VERSION ""

NS_ :

BS_:

BU_: TestBoard DummyBoard

BO_ 2147483655 InitTestphase: 2 TestBoard
 SG_ TestNumber : 8|8@1+ (1,0) [0|0] "" TestBoard
 SG_ TestVersion : 0|8@1+ (1,0) [0|0] "" TestBoard

BO_ 2147483666 TestMessage1: 1 TestBoard
 SG_ TestSignal : 0|8@1+ (1,0) [0|1] ""  TestBoard

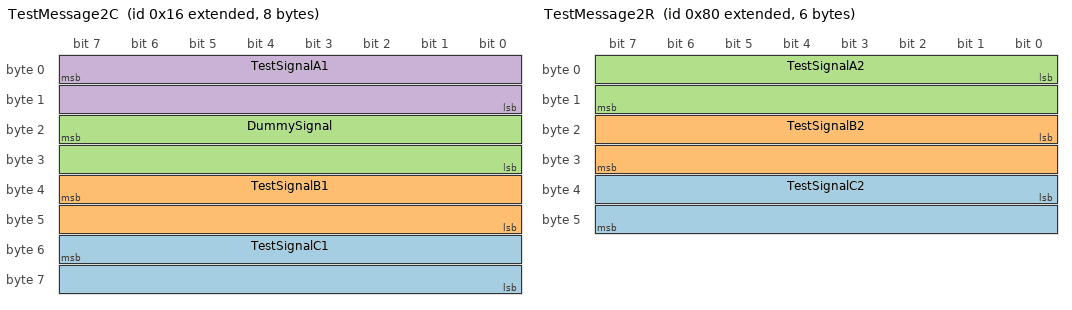
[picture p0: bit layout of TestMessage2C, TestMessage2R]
BO_ 2147483670 TestMessage2C: 8 TestBoard
 SG_ TestSignalC1 : 55|16@0- (1,0) [0|0] ""  TestBoard
 SG_ TestSignalB1 : 39|16@0- (1,0) [0|0] ""  TestBoard
 SG_ DummySignal : 23|16@0- (1,0) [0|0] ""  DummyBoard
 SG_ TestSignalA1 : 7|16@0- (1,0) [0|0] ""  TestBoard

BO_ 2147483776 TestMessage2R: 6 TestBoard
 SG_ TestSignalC2 : 32|16@1+ (1,0) [0|0] ""  TestBoard
 SG_ TestSignalB2 : 16|16@1+ (1,0) [0|0] ""  TestBoard
 SG_ TestSignalA2 : 0|16@1+ (1,0) [0|0] ""  TestBoard

BO_ 2147483876 TestMessage3A: 6 TestBoard
 SG_ TestSignalA : 32|16@1+ (1,0) [0|0] ""  TestBoard

BO_ 2147483877 TestMessage3B: 6 TestBoard
 SG_ TestSignalB : 32|16@1+ (1,0) [0|0] ""  TestBoard

BO_ 2147483878 TestMessage4A: 1 TestBoard
 SG_ TestSignal4A : 0|8@1+ (1,0) [0|1] ""  TestBoard

BO_ 2147483879 TestMessage4B: 1 TestBoard
 SG_ TestSignal4B : 0|8@1+ (1,0) [0|1] ""  TestBoard

BO_ 2147484567 DummyMessage: 6 DummyBoard
 SG_ DummySignalB : 32|16@1+ (1,0) [0|0] ""  TestBoard
 SG_ DummySignalA : 16|8@1+ (1,0) [0|0] ""  TestBoard
